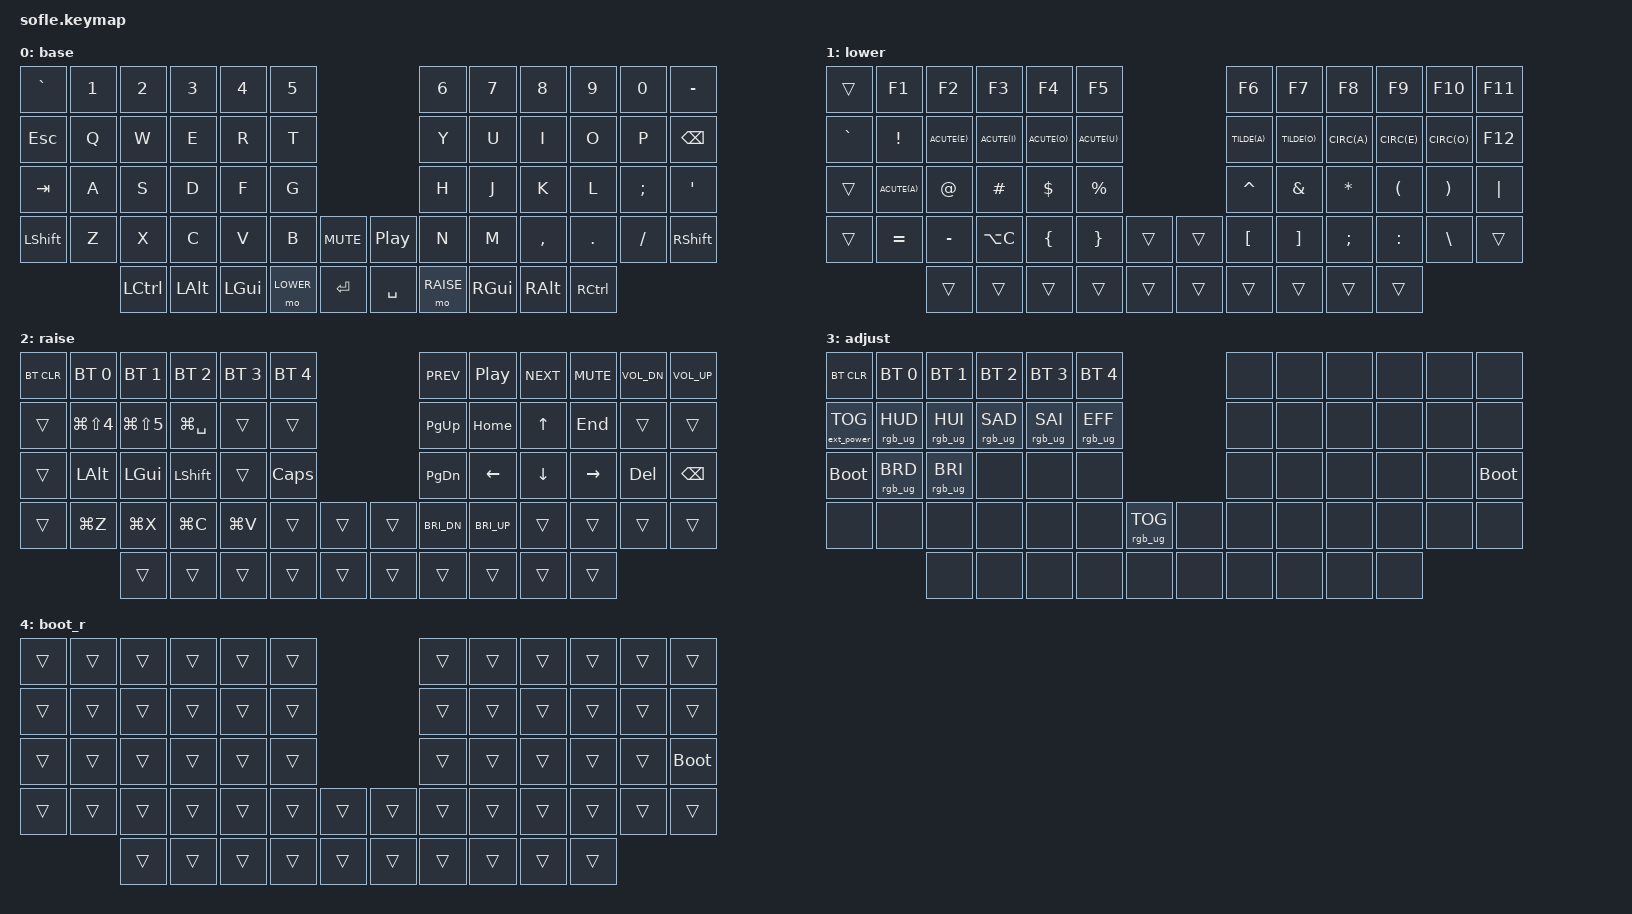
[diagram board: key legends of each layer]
/*
 * Copyright (c) 2020 The ZMK Contributors
 *
 * SPDX-License-Identifier: MIT
 *
 * Mac layout, tuned for the macOS "Brasileiro - Pro" input source
 * (US-based with dead keys: ' + c = ç, ~ + a = ã, ^ + e = ê).
 */

#include <behaviors.dtsi>
#include <dt-bindings/zmk/keys.h>
#include <dt-bindings/zmk/bt.h>
#include <dt-bindings/zmk/rgb.h>
#include <dt-bindings/zmk/ext_power.h>

#define BASE 0
#define LOWER 1
#define RAISE 2
#define ADJUST 3
#define BOOT_R 4

// Accent shortcuts: tap a dead key, then a letter (lowercase only).
#define ACUTE(letter) &dk SQT letter
#define TILDE(letter) &dk LS(GRAVE) letter
#define CIRC(letter)  &dk LS(N6) letter
// Option+C gives ç (and Ç with Shift held) on Brasileiro - Pro.
#define CEDIL &kp LA(C)

/ {

    macros {
        // &dk <dead key> <letter>: taps the dead key, then the letter.
        dk: dead_key {
            compatible = "zmk,behavior-macro-two-param";
            #binding-cells = <2>;
            wait-ms = <0>;
            tap-ms = <10>;
            bindings
                = <&macro_param_1to1>
                , <&macro_tap &kp MACRO_PLACEHOLDER>
                , <&macro_param_2to1>
                , <&macro_tap &kp MACRO_PLACEHOLDER>
                ;
        };
    };

    // Bootloader shortcuts (no need to open the case to reach RST).
    // Combos always run on the central (left) half, so:
    // LEFT half:  press ` + ESC + TAB together.
    // RIGHT half: hold the two top outer keys (- and BKSPC), then press '.
    //             The combo only enables the BOOT_R layer; the ' key press
    //             comes from the right half, so the right half resets.
    // Backup: hold LOWER + RAISE and press TAB (left) or ' (right).
    combos {
        compatible = "zmk,combos";
        combo_bootloader_left {
            timeout-ms = <80>;
            key-positions = <0 12 24>;
            bindings = <&bootloader>;
        };
        combo_boot_layer_right {
            timeout-ms = <80>;
            key-positions = <11 23>;
            bindings = <&mo BOOT_R>;
        };
    };

    // Activate ADJUST layer by pressing raise and lower
    conditional_layers {
        compatible = "zmk,conditional-layers";
        adjust_layer {
            if-layers = <LOWER RAISE>;
            then-layer = <ADJUST>;
        };
    };

    keymap {
        compatible = "zmk,keymap";

        default_layer {
            display-name = "base";
// ------------------------------------------------------------------------------------------------------------
// |   `   |  1  |  2  |  3   |  4   |  5   |                   |  6   |  7    |  8    |  9   |   0   |   -   |
// |  ESC  |  Q  |  W  |  E   |  R   |  T   |                   |  Y   |  U    |  I    |  O   |   P   | BKSPC |
// |  TAB  |  A  |  S  |  D   |  F   |  G   |                   |  H   |  J    |  K    |  L   |   ;   |   '   |
// | SHIFT |  Z  |  X  |  C   |  V   |  B   |  MUTE  |  | PLAY  |  N   |  M    |  ,    |  .   |   /   | SHIFT |
//               | CTRL | OPT | CMD  | LOWER|  ENTER |  | SPACE | RAISE| CMD   | OPT   | CTRL |
            bindings = <
&kp GRAVE &kp N1 &kp N2    &kp N3    &kp N4   &kp N5                           &kp N6 &kp N7    &kp N8    &kp N9    &kp N0   &kp MINUS
&kp ESC   &kp Q  &kp W     &kp E     &kp R    &kp T                            &kp Y  &kp U     &kp I     &kp O     &kp P    &kp BSPC
&kp TAB   &kp A  &kp S     &kp D     &kp F    &kp G                            &kp H  &kp J     &kp K     &kp L     &kp SEMI &kp SQT
&kp LSHFT &kp Z  &kp X     &kp C     &kp V    &kp B      &kp C_MUTE &kp C_PP   &kp N  &kp M     &kp COMMA &kp DOT   &kp FSLH &kp RSHFT
                 &kp LCTRL &kp LALT  &kp LGUI &mo LOWER  &kp RET    &kp SPACE  &mo RAISE  &kp RGUI  &kp RALT  &kp RCTRL
            >;

            sensor-bindings = <&inc_dec_kp C_VOL_UP C_VOL_DN &inc_dec_kp PG_UP PG_DN>;
        };

        lower_layer {
            display-name = "lower";
// ------------------------------------------------------------------------------------------------------------
// |       |  F1 |  F2 |  F3  |  F4  |  F5  |                   |  F6  |  F7   |  F8   |  F9  |  F10  |  F11  |
// |   `   |  !  |  é  |  í   |  ó   |  ú   |                   |  ã   |  õ    |  â    |  ê   |   ô   |  F12  |
// |       |  á  |  @  |  #   |  $   |  %   |                   |  ^   |  &    |  *    |  (   |   )   |   |   |
// |       |  =  |  -  |  ç   |  {   |  }   |        |  |       |  [   |  ]    |  ;    |  :   |   \   |       |
//               |     |      |      |      |        |  |       |      |       |       |      |
            bindings = <
&trans    &kp F1      &kp F2      &kp F3      &kp F4      &kp F5                     &kp F6      &kp F7      &kp F8     &kp F9     &kp F10    &kp F11
&kp GRAVE &kp EXCL    ACUTE(E)    ACUTE(I)    ACUTE(O)    ACUTE(U)                   TILDE(A)    TILDE(O)    CIRC(A)    CIRC(E)    CIRC(O)    &kp F12
&trans    ACUTE(A)    &kp AT      &kp HASH    &kp DLLR    &kp PRCNT                  &kp CARET   &kp AMPS    &kp ASTRK  &kp LPAR   &kp RPAR   &kp PIPE
&trans    &kp EQUAL   &kp MINUS   CEDIL       &kp LBRC    &kp RBRC    &trans &trans  &kp LBKT    &kp RBKT    &kp SEMI   &kp COLON  &kp BSLH   &trans
                      &trans      &trans      &trans      &trans      &trans &trans  &trans      &trans      &trans     &trans
            >;

            sensor-bindings = <&inc_dec_kp C_VOL_UP C_VOL_DN &inc_dec_kp PG_UP PG_DN>;
        };

        raise_layer {
            display-name = "raise";
// ------------------------------------------------------------------------------------------------------------
// | BTCLR | BT1  | BT2  |  BT3  |  BT4  |  BT5 |                | PREV | PLAY | NEXT  | MUTE | VOL-  | VOL+  |
// |       | PRT▢ | PRT  | SPOTL |       |      |                | PGUP | HOME |   ^   | END  |       |       |
// |       | OPT  | CMD  | SHIFT |       | CAPS |                | PGDN |   <- |   v   |  ->  |  DEL  | BKSPC |
// |       | UNDO | CUT  | COPY  | PASTE |      |      |  |      | BRI- | BRI+ |       |      |       |       |
//                |      |       |       |      |      |  |      |      |      |       |      |
            bindings = <
&bt BT_CLR &bt BT_SEL 0     &bt BT_SEL 1     &bt BT_SEL 2  &bt BT_SEL 3 &bt BT_SEL 4                  &kp C_PREV   &kp C_PP     &kp C_NEXT &kp C_MUTE &kp C_VOL_DN &kp C_VOL_UP
&trans     &kp LG(LS(N4))   &kp LG(LS(N5))   &kp LG(SPACE) &trans       &trans                        &kp PG_UP    &kp HOME     &kp UP     &kp END    &trans       &trans
&trans     &kp LALT         &kp LGUI         &kp LSHFT     &trans       &kp CAPS                      &kp PG_DN    &kp LEFT     &kp DOWN   &kp RIGHT  &kp DEL      &kp BSPC
&trans     &kp LG(Z)        &kp LG(X)        &kp LG(C)     &kp LG(V)    &trans        &trans  &trans  &kp C_BRI_DN &kp C_BRI_UP &trans     &trans     &trans       &trans
                            &trans           &trans        &trans       &trans        &trans  &trans  &trans       &trans       &trans     &trans
            >;

            sensor-bindings = <&inc_dec_kp C_VOL_UP C_VOL_DN &inc_dec_kp PG_UP PG_DN>;
        };

        adjust_layer {
// ----------------------------------------------------------------------------------------------------------------------------
// | BTCLR  |  BT1    |  BT2    |   BT3   |   BT4   |   BT5   |                  |      |      |       |      |       |       |
// | EXTPWR | RGB_HUD | RGB_HUI | RGB_SAD | RGB_SAI | RGB_EFF |                  |      |      |       |      |       |       |
// | BOOTLD | RGB_BRD | RGB_BRI |         |         |         |                  |      |      |       |      |       | BOOTLD|
// |        |         |         |         |         |         | RGB_TOG | |      |      |      |       |      |       |       |
//                    |         |         |         |         |         | |      |      |      |       |      |
            display-name = "adjust";
            bindings = <
&bt BT_CLR        &bt BT_SEL 0    &bt BT_SEL 1    &bt BT_SEL 2    &bt BT_SEL 3    &bt BT_SEL 4                            &none &none &none &none &none &none
&ext_power EP_TOG &rgb_ug RGB_HUD &rgb_ug RGB_HUI &rgb_ug RGB_SAD &rgb_ug RGB_SAI &rgb_ug RGB_EFF                         &none &none &none &none &none &none
&bootloader       &rgb_ug RGB_BRD &rgb_ug RGB_BRI &none           &none           &none                                   &none &none &none &none &none &bootloader
&none             &none           &none           &none           &none           &none            &rgb_ug RGB_TOG &none  &none &none &none &none &none &none
                                  &none           &none           &none           &none            &none           &none  &none &none &none &none
            >;
        };

        boot_right_layer {
            display-name = "boot_r";
            bindings = <
&trans &trans &trans &trans &trans &trans                &trans &trans &trans &trans &trans &trans
&trans &trans &trans &trans &trans &trans                &trans &trans &trans &trans &trans &trans
&trans &trans &trans &trans &trans &trans                &trans &trans &trans &trans &trans &bootloader
&trans &trans &trans &trans &trans &trans &trans  &trans &trans &trans &trans &trans &trans &trans
              &trans &trans &trans &trans &trans  &trans &trans &trans &trans &trans
            >;
        };

    };
};
